# STM32H753x register map
File version: 1.0
CPU: CM7 r0p1, little endian, MPU, FPU, 4 interrupt priority bits
Registers are 32-bit, read-write, reset 0x0 unless marked. A register's access mark holds for its fields unless they carry their own. Offsets are from the block's base; [hi:lo] are bit positions.

## Ethernet_DMA — Ethernet: DMA mode register (DMA)
Base 0x40029000
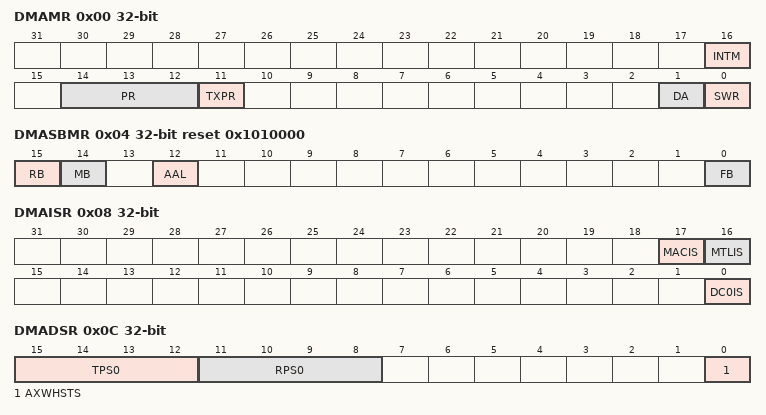
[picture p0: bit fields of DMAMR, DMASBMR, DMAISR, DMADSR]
0x00 DMAMR access per field — DMA mode register
  [16] INTM rw — Interrupt Mode
  [14:12] PR ro — Priority ratio
  [11] TXPR ro — Transmit priority
  [1] DA ro — DMA Tx or Rx Arbitration Scheme
  [0] SWR rw — Software Reset
0x04 DMASBMR access per field reset 0x1010000 — System bus mode register
  [15] RB ro — Rebuild INCRx Burst
  [14] MB ro — Mixed Burst
  [12] AAL rw — Address-Aligned Beats
  [0] FB rw — Fixed Burst Length
0x08 DMAISR ro — Interrupt status register
  [17] MACIS — MAC Interrupt Status
  [16] MTLIS — MTL Interrupt Status
  [0] DC0IS — DMA Channel Interrupt Status
0x0C DMADSR ro — Debug status register
  [15:12] TPS0 — DMA Channel Transmit Process State
  [11:8] RPS0 — DMA Channel Receive Process State
  [0] AXWHSTS — AHB Master Write Channel
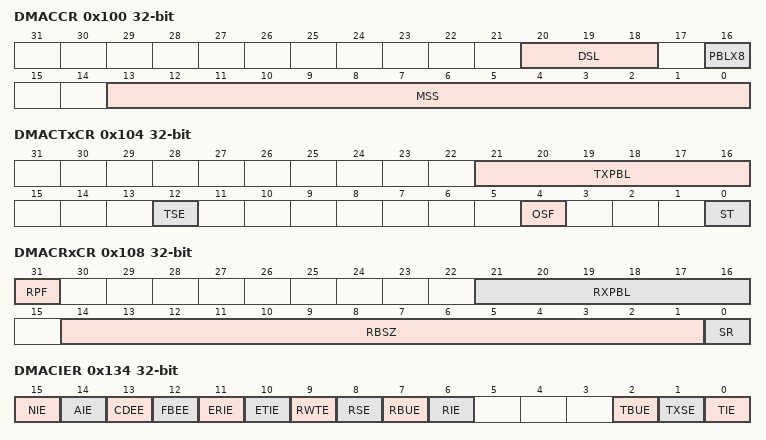
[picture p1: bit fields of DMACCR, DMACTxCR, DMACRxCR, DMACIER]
0x100 DMACCR — Channel control register
  [20:18] DSL — Descriptor Skip Length
  [16] PBLX8 — 8xPBL mode
  [13:0] MSS — Maximum Segment Size
0x104 DMACTxCR — Channel transmit control register
  [21:16] TXPBL — Transmit Programmable Burst Length
  [12] TSE — TCP Segmentation Enabled
  [4] OSF — Operate on Second Packet
  [0] ST — Start or Stop Transmission Command
0x108 DMACRxCR — Channel receive control register
  [31] RPF — DMA Rx Channel Packet Flush
  [21:16] RXPBL
  [14:1] RBSZ — Receive Buffer size
  [0] SR — Start or Stop Receive Command
0x114 DMACTxDLAR — Channel Tx descriptor list address register
  [31:2] TDESLA — Start of Transmit List
0x11C DMACRxDLAR — Channel Rx descriptor list address register
  [31:2] RDESLA — Start of Receive List
0x120 DMACTxDTPR — Channel Tx descriptor tail pointer register
  [31:2] TDT — Transmit Descriptor Tail Pointer
0x128 DMACRxDTPR — Channel Rx descriptor tail pointer register
  [31:2] RDT — Receive Descriptor Tail Pointer
0x12C DMACTxRLR — Channel Tx descriptor ring length register
  [9:0] TDRL — Transmit Descriptor Ring Length
0x130 DMACRxRLR — Channel Rx descriptor ring length register
  [9:0] RDRL — Receive Descriptor Ring Length
0x134 DMACIER — Channel interrupt enable register
  [15] NIE — Normal Interrupt Summary Enable
  [14] AIE — Abnormal Interrupt Summary Enable
  [13] CDEE — Context Descriptor Error Enable
  [12] FBEE — Fatal Bus Error Enable
  [11] ERIE — Early Receive Interrupt Enable
  [10] ETIE — Early Transmit Interrupt Enable
  [9] RWTE — Receive Watchdog Timeout Enable
  [8] RSE — Receive Stopped Enable
  [7] RBUE — Receive Buffer Unavailable Enable
  [6] RIE — Receive Interrupt Enable
  [2] TBUE — Transmit Buffer Unavailable Enable
  [1] TXSE — Transmit Stopped Enable
  [0] TIE — Transmit Interrupt Enable
0x138 DMACRxIWTR — Channel Rx interrupt watchdog timer register
  [7:0] RWT — Receive Interrupt Watchdog Timer Count
0x144 DMACCATxDR ro — Channel current application transmit descriptor register
  [31:0] CURTDESAPTR — Application Transmit Descriptor Address Pointer
0x14C DMACCARxDR ro — Channel current application receive descriptor register
  [31:0] CURRDESAPTR — Application Receive Descriptor Address Pointer
0x154 DMACCATxBR ro — Channel current application transmit buffer register
  [31:0] CURTBUFAPTR — Application Transmit Buffer Address Pointer
0x15C DMACCARxBR ro — Channel current application receive buffer register
  [31:0] CURRBUFAPTR — Application Receive Buffer Address Pointer
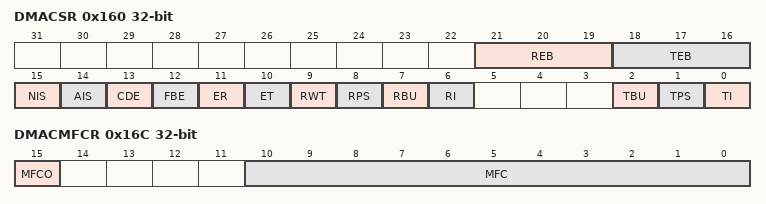
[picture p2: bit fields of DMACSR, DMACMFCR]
0x160 DMACSR access per field — Channel status register
  [21:19] REB ro — Rx DMA Error Bits
  [18:16] TEB ro — Tx DMA Error Bits
  [15] NIS rw — Normal Interrupt Summary
  [14] AIS rw — Abnormal Interrupt Summary
  [13] CDE rw — Context Descriptor Error
  [12] FBE rw — Fatal Bus Error
  [11] ER rw — Early Receive Interrupt
  [10] ET rw — Early Transmit Interrupt
  [9] RWT rw — Receive Watchdog Timeout
  [8] RPS rw — Receive Process Stopped
  [7] RBU rw — Receive Buffer Unavailable
  [6] RI rw — Receive Interrupt
  [2] TBU rw — Transmit Buffer Unavailable
  [1] TPS rw — Transmit Process Stopped
  [0] TI rw — Transmit Interrupt
0x16C DMACMFCR ro — Channel missed frame count register
  [15] MFCO — Overflow status of the MFC Counter
  [10:0] MFC — Dropped Packet Counters
